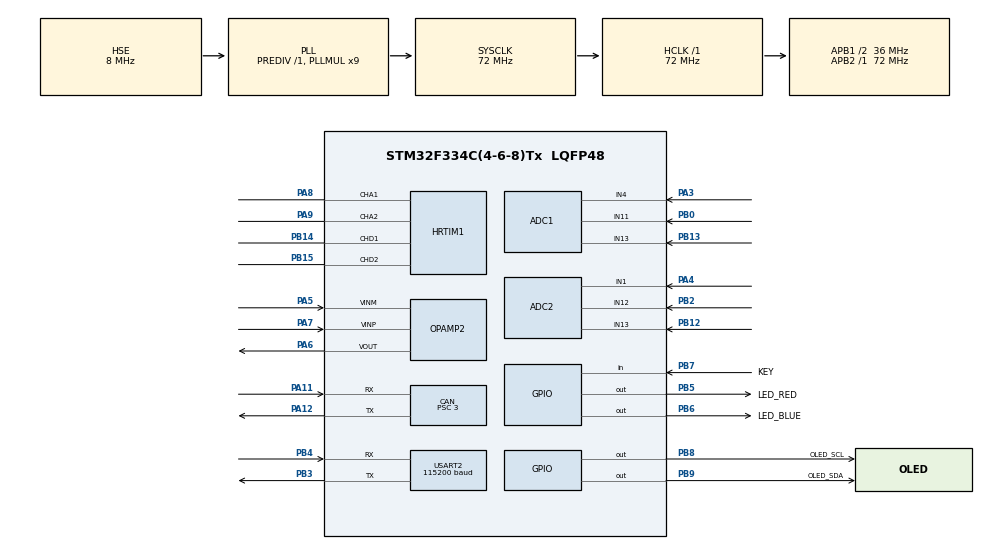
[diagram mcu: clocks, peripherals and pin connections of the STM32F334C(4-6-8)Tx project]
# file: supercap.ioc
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ADC1.Channel-0\#ChannelRegularConversion=ADC_CHANNEL_4
ADC1.Channel-1\#ChannelRegularConversion=ADC_CHANNEL_11
ADC1.Channel-2\#ChannelRegularConversion=ADC_CHANNEL_13
ADC1.ClockPrescaler=ADC_CLOCK_SYNC_PCLK_DIV1
ADC1.ContinuousConvMode=ENABLE
ADC1.DMAContinuousRequests=ENABLE
ADC1.EnableInjectedConversion=DISABLE
ADC1.ExternalTrigConv=ADC_SOFTWARE_START
ADC1.NbrOfConversion=3
ADC1.NbrOfConversionFlag=1
ADC1.Offset-0\#ChannelRegularConversion=0
ADC1.Offset-1\#ChannelRegularConversion=0
ADC1.Offset-2\#ChannelRegularConversion=0
ADC1.OffsetNumber-0\#ChannelRegularConversion=ADC_OFFSET_NONE
ADC1.OffsetNumber-1\#ChannelRegularConversion=ADC_OFFSET_NONE
ADC1.OffsetNumber-2\#ChannelRegularConversion=ADC_OFFSET_NONE
ADC1.Overrun=ADC_OVR_DATA_PRESERVED
ADC1.Rank-0\#ChannelRegularConversion=1
ADC1.Rank-1\#ChannelRegularConversion=2
ADC1.Rank-2\#ChannelRegularConversion=3
ADC1.SamplingTime-0\#ChannelRegularConversion=ADC_SAMPLETIME_601CYCLES_5
ADC1.SamplingTime-1\#ChannelRegularConversion=ADC_SAMPLETIME_601CYCLES_5
ADC1.SamplingTime-2\#ChannelRegularConversion=ADC_SAMPLETIME_601CYCLES_5
ADC1.SubFamily=STM32F334x8
ADC1.master=1
ADC2.Channel-0\#ChannelRegularConversion=ADC_CHANNEL_13
ADC2.Channel-1\#ChannelRegularConversion=ADC_CHANNEL_12
ADC2.Channel-2\#ChannelRegularConversion=ADC_CHANNEL_1
ADC2.ClockPrescaler=ADC_CLOCK_SYNC_PCLK_DIV1
ADC2.ContinuousConvMode=ENABLE
ADC2.DMAContinuousRequests=ENABLE
ADC2.EnableInjectedConversion=DISABLE
ADC2.NbrOfConversion=3
ADC2.NbrOfConversionFlag=1
ADC2.Offset-0\#ChannelRegularConversion=0
ADC2.Offset-1\#ChannelRegularConversion=0
ADC2.Offset-2\#ChannelRegularConversion=0
ADC2.OffsetNumber-0\#ChannelRegularConversion=ADC_OFFSET_NONE
ADC2.OffsetNumber-1\#ChannelRegularConversion=ADC_OFFSET_NONE
ADC2.OffsetNumber-2\#ChannelRegularConversion=ADC_OFFSET_NONE
ADC2.Overrun=ADC_OVR_DATA_PRESERVED
ADC2.Rank-0\#ChannelRegularConversion=1
ADC2.Rank-1\#ChannelRegularConversion=2
ADC2.Rank-2\#ChannelRegularConversion=3
ADC2.SamplingTime-0\#ChannelRegularConversion=ADC_SAMPLETIME_601CYCLES_5
ADC2.SamplingTime-1\#ChannelRegularConversion=ADC_SAMPLETIME_601CYCLES_5
ADC2.SamplingTime-2\#ChannelRegularConversion=ADC_SAMPLETIME_601CYCLES_5
ADC2.SamplingTimeOPAMP-1\#ChannelRegularConversion=ADC_SAMPLETIME_61CYCLES_5
ADC2.SamplingTimeOPAMP-2\#ChannelRegularConversion=ADC_SAMPLETIME_61CYCLES_5
ADC2.SubFamily=STM32F334x8
CAN.ABOM=DISABLE
CAN.BS1=CAN_BS1_7TQ
CAN.BS2=CAN_BS2_4TQ
CAN.CalculateBaudRate=1000000
CAN.CalculateTimeBit=999.99
CAN.CalculateTimeQuantum=83.33333333333334
CAN.NART=DISABLE
CAN.Prescaler=3
CAN.TXFP=ENABLE
Dma.ADC1.0.Direction=DMA_PERIPH_TO_MEMORY
Dma.ADC1.0.Instance=DMA1_Channel1
Dma.ADC1.0.MemDataAlignment=DMA_MDATAALIGN_HALFWORD
Dma.ADC1.0.MemInc=DMA_MINC_ENABLE
Dma.ADC1.0.Mode=DMA_CIRCULAR
Dma.ADC1.0.PeriphDataAlignment=DMA_PDATAALIGN_HALFWORD
Dma.ADC1.0.PeriphInc=DMA_PINC_DISABLE
Dma.ADC1.0.Priority=DMA_PRIORITY_HIGH
Dma.ADC2.1.Direction=DMA_PERIPH_TO_MEMORY
Dma.ADC2.1.Instance=DMA1_Channel2
Dma.ADC2.1.MemDataAlignment=DMA_MDATAALIGN_HALFWORD
Dma.ADC2.1.MemInc=DMA_MINC_ENABLE
Dma.ADC2.1.Mode=DMA_CIRCULAR
Dma.ADC2.1.PeriphDataAlignment=DMA_PDATAALIGN_HALFWORD
Dma.ADC2.1.PeriphInc=DMA_PINC_DISABLE
Dma.ADC2.1.Priority=DMA_PRIORITY_HIGH
Dma.Request0=ADC1
Dma.Request1=ADC2
FREERTOS.Tasks01=defaultTask,24,256,StartDefaultTask,Default,NULL,Dynamic,NULL,NULL;OLED,8,512,StartOLED,As weak,NULL,Dynamic,NULL,NULL;cap_loop,32,512,Startcap_loop,As weak,NULL,Dynamic,NULL,NULL
FREERTOS.configTOTAL_HEAP_SIZE=6000
HRTIM1.CompareUnit1-Output_TA1TA2=HRTIM_COMPAREUNIT_1
HRTIM1.CompareUnit1-Output_TD1TD2=HRTIM_COMPAREUNIT_1
HRTIM1.CompareUnit2-Output_TA1TA2=HRTIM_COMPAREUNIT_2
HRTIM1.CompareUnit2-Output_TD1TD2=HRTIM_COMPAREUNIT_2
HRTIM1.DeadTimeInsertion-Output_TA1TA2=HRTIM_TIMDEADTIMEINSERTION_ENABLED
HRTIM1.DeadTimeInsertion-Output_TD1TD2=HRTIM_TIMDEADTIMEINSERTION_ENABLED
HRTIM1.FallingValue-Output_TA1TA2=300
HRTIM1.FallingValue-Output_TD1TD2=350
HRTIM1.NumberInterruptRequests_Master-MasterTimer=0
HRTIM1.NumberResetSource1-Output_TA1TA2=1
HRTIM1.NumberResetSource1-Output_TD1TD2=1
HRTIM1.NumberResetTrigger-Output_TA1TA2=1
HRTIM1.NumberResetTrigger-Output_TD1TD2=1
HRTIM1.NumberSetSource1-Output_TA1TA2=1
HRTIM1.NumberSetSource1-Output_TD1TD2=1
HRTIM1.Periode_MASTER=46080
HRTIM1.Periode_TA=46080
HRTIM1.Periode_TD=46080
HRTIM1.PreloadEnable-MasterTimer=HRTIM_PRELOAD_ENABLED
HRTIM1.PreloadEnable-Output_TA1TA2=HRTIM_PRELOAD_ENABLED
HRTIM1.PreloadEnable-Output_TD1TD2=HRTIM_PRELOAD_ENABLED
HRTIM1.PrescalerDead-Output_TD1TD2=HRTIM_TIMDEADTIME_PRESCALERRATIO_MUL4
HRTIM1.RepetitionUpdate-MasterTimer=HRTIM_UPDATEONREPETITION_ENABLED
HRTIM1.RepetitionUpdate-Output_TA1TA2=HRTIM_UPDATEONREPETITION_ENABLED
HRTIM1.RepetitionUpdate-Output_TD1TD2=HRTIM_UPDATEONREPETITION_ENABLED
HRTIM1.ResetOutput1_Source1-Output_TA1TA2=HRTIM_OUTPUTRESET_TIMCMP2
HRTIM1.ResetOutput1_Source1-Output_TD1TD2=HRTIM_OUTPUTRESET_TIMCMP2
HRTIM1.ResetTrigger1-Output_TA1TA2=HRTIM_TIMRESETTRIGGER_MASTER_PER
HRTIM1.ResetTrigger1-Output_TD1TD2=HRTIM_TIMRESETTRIGGER_MASTER_PER
HRTIM1.RisingValue-Output_TA1TA2=300
HRTIM1.RisingValue-Output_TD1TD2=350
HRTIM1.SetOutput1_Source1-Output_TA1TA2=HRTIM_OUTPUTSET_TIMCMP1
HRTIM1.SetOutput1_Source1-Output_TD1TD2=HRTIM_OUTPUTSET_TIMCMP1
Mcu.Family=STM32F3
Mcu.Name=STM32F334C(4-6-8)Tx
Mcu.Package=LQFP48
NVIC.CAN_RX0_IRQn=true\:5\:0\:true\:false\:true\:true\:true\:true
NVIC.DMA1_Channel1_IRQn=true\:5\:0\:false\:false\:true\:true\:false\:true
NVIC.DMA1_Channel2_IRQn=true\:5\:0\:false\:false\:true\:true\:false\:true
NVIC.PriorityGroup=NVIC_PRIORITYGROUP_4
NVIC.TIM2_IRQn=true\:5\:0\:true\:false\:true\:true\:true\:true
NVIC.TIM3_IRQn=true\:15\:0\:false\:false\:true\:false\:false\:true
NVIC.TimeBase=TIM3_IRQn
NVIC.TimeBaseIP=TIM3
OPAMP2.SelfCalibration=Disable
PA11.Mode=CAN_Activate
PA11.Signal=CAN_RX
PA12.Mode=CAN_Activate
PA12.Signal=CAN_TX
PA13.Mode=Serial_Wire
PA13.Signal=SYS_JTMS-SWDIO
PA14.Mode=Serial_Wire
PA14.Signal=SYS_JTCK-SWCLK
PA3.Mode=IN4-Single-Ended
PA3.Signal=ADC1_IN4
PA4.Mode=IN1-Single-Ended
PA4.Signal=ADC2_IN1
PA5.Mode=Standalone
PA5.Signal=OPAMP2_VINM
PA6.Mode=Standalone
PA6.Signal=OPAMP2_VOUT
PA7.Mode=Standalone
PA7.Signal=OPAMP2_VINP
PA8.Mode=Output_TA1TA2
PA8.Signal=HRTIM1_CHA1
PA9.Mode=Output_TA1TA2
PA9.Signal=HRTIM1_CHA2
PB0.Mode=IN11-Single-Ended
PB0.Signal=ADC1_IN11
PB12.Mode=IN13-Single-Ended
PB12.Signal=ADC2_IN13
PB13.Mode=IN13-Single-Ended
PB13.Signal=ADC1_IN13
PB14.Mode=Output_TD1TD2
PB14.Signal=HRTIM1_CHD1
PB15.Mode=Output_TD1TD2
PB15.Signal=HRTIM1_CHD2
PB2.Mode=IN12-Single-Ended
PB2.Signal=ADC2_IN12
PB3.Mode=Asynchronous
PB3.Signal=USART2_TX
PB4.Mode=Asynchronous
PB4.Signal=USART2_RX
PB5.GPIO_Label=LED_RED
PB5.Signal=GPIO_Output
PB6.GPIO_Label=LED_BLUE
PB6.Signal=GPIO_Output
PB7.GPIO_Label=KEY
PB7.Signal=GPIO_Input
PB8.GPIO_Label=OLED_SCL
PB8.GPIO_Speed=GPIO_SPEED_FREQ_HIGH
PB8.Signal=GPIO_Output
PB9.GPIO_Label=OLED_SDA
PB9.GPIO_ModeDefaultOutputPP=GPIO_MODE_OUTPUT_OD
PB9.GPIO_PuPd=GPIO_NOPULL
PB9.GPIO_Speed=GPIO_SPEED_FREQ_HIGH
PB9.Signal=GPIO_Output
PF0\ /\ OSC_IN.Mode=HSE-External-Oscillator
PF0\ /\ OSC_IN.Signal=RCC_OSC_IN
PF1\ /\ OSC_OUT.Mode=HSE-External-Oscillator
PF1\ /\ OSC_OUT.Signal=RCC_OSC_OUT
ProjectManager.HeapSize=0x200
ProjectManager.StackSize=0x400
ProjectManager.TargetToolchain=MDK-ARM V5.32
RCC.AHBFreq_Value=72000000
RCC.APB1CLKDivider=RCC_HCLK_DIV2
RCC.APB1Freq_Value=36000000
RCC.APB1TimFreq_Value=72000000
RCC.APB2Freq_Value=72000000
RCC.APB2TimFreq_Value=72000000
RCC.CortexFreq_Value=72000000
RCC.HCLKFreq_Value=72000000
RCC.HRTIMSelection=RCC_HRTIM1CLK_PLLCLK
RCC.HSE_VALUE=8000000
RCC.HSI_VALUE=8000000
RCC.LSE_VALUE=32768
RCC.PLLMUL=RCC_PLL_MUL9
RCC.PLLSourceVirtual=RCC_PLLSOURCE_HSE
RCC.SYSCLKFreq_VALUE=72000000
RCC.SYSCLKSourceVirtual=RCC_SYSCLKSOURCE_PLLCLK
TIM2.AutoReloadPreload=TIM_AUTORELOAD_PRELOAD_ENABLE
TIM2.Period=99
TIM2.Prescaler=71
USART2.BaudRate=115200
USART2.VirtualMode-Asynchronous=VM_ASYNC
VP_FREERTOS_VS_CMSIS_V2.Mode=CMSIS_V2
VP_HRTIM1_VS_hrtimMasterTimerNoOutput.Mode=MasterTimer
VP_SYS_VS_tim3.Mode=TIM3
VP_TIM2_VS_ClockSourceINT.Mode=Internal
board=custom

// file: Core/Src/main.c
/* USER CODE BEGIN Header */
/**
  ******************************************************************************
  * @file           : main.c
  * @brief          : Main program body
  ******************************************************************************
  * @attention
  *
  * <h2><center>&copy; Copyright (c) 2021 STMicroelectronics.
  * All rights reserved.</center></h2>
  *
  * This software component is licensed by ST under BSD 3-Clause license,
  * the "License"; You may not use this file except in compliance with the
  * License. You may obtain a copy of the License at:
  *                        opensource.org/licenses/BSD-3-Clause
  *
  ******************************************************************************
  */
/* USER CODE END Header */
#include "main.h"
#include "cmsis_os.h"
#include "adc.h"
#include "can.h"
#include "dma.h"
#include "hrtim.h"
#include "hrtim.h"
#include "opamp.h"
#include "tim.h"
#include "usart.h"
#include "gpio.h"

/* USER CODE BEGIN Includes */
#include "cap.h"
/* USER CODE END Includes */

void SystemClock_Config(void);
void MX_FREERTOS_Init(void);

int main(void)
{

  /* MCU Configuration--------------------------------------------------------*/

  /* Reset of all peripherals, Initializes the Flash interface and the Systick. */
  HAL_Init();

  /* Configure the system clock */
  SystemClock_Config();

  /* Initialize all configured peripherals */
  MX_GPIO_Init();
  MX_CAN_Init();
  MX_DMA_Init();
  MX_ADC1_Init();
  MX_ADC2_Init();
  MX_OPAMP2_Init();
  MX_TIM2_Init();
  MX_HRTIM1_Init();
  MX_USART2_UART_Init();
  /* USER CODE BEGIN 2 */
    system_init();
  /* USER CODE END 2 */

  /* Init scheduler */
  osKernelInitialize();  /* Call init function for freertos objects (in freertos.c) */
  MX_FREERTOS_Init();
  /* Start scheduler */
  osKernelStart();

  /* We should never get here as control is now taken by the scheduler */
  /* Infinite loop */
  while (1)
  {

  }
}

void SystemClock_Config(void)
{
  RCC_OscInitTypeDef RCC_OscInitStruct = {0};
  RCC_ClkInitTypeDef RCC_ClkInitStruct = {0};
  RCC_PeriphCLKInitTypeDef PeriphClkInit = {0};

  /** Initializes the RCC Oscillators according to the specified parameters
  * in the RCC_OscInitTypeDef structure.
  */
  RCC_OscInitStruct.OscillatorType = RCC_OSCILLATORTYPE_HSE;
  RCC_OscInitStruct.HSEState = RCC_HSE_ON;
  RCC_OscInitStruct.HSEPredivValue = RCC_HSE_PREDIV_DIV1;
  RCC_OscInitStruct.HSIState = RCC_HSI_ON;
  RCC_OscInitStruct.PLL.PLLState = RCC_PLL_ON;
  RCC_OscInitStruct.PLL.PLLSource = RCC_PLLSOURCE_HSE;
  RCC_OscInitStruct.PLL.PLLMUL = RCC_PLL_MUL9;
  if (HAL_RCC_OscConfig(&RCC_OscInitStruct) != HAL_OK)
  {
    Error_Handler();
  }
  /** Initializes the CPU, AHB and APB buses clocks
  */
  RCC_ClkInitStruct.ClockType = RCC_CLOCKTYPE_HCLK|RCC_CLOCKTYPE_SYSCLK
                              |RCC_CLOCKTYPE_PCLK1|RCC_CLOCKTYPE_PCLK2;
  RCC_ClkInitStruct.SYSCLKSource = RCC_SYSCLKSOURCE_PLLCLK;
  RCC_ClkInitStruct.AHBCLKDivider = RCC_SYSCLK_DIV1;
  RCC_ClkInitStruct.APB1CLKDivider = RCC_HCLK_DIV2;
  RCC_ClkInitStruct.APB2CLKDivider = RCC_HCLK_DIV1;

  if (HAL_RCC_ClockConfig(&RCC_ClkInitStruct, FLASH_LATENCY_2) != HAL_OK)
  {
    Error_Handler();
  }
  PeriphClkInit.PeriphClockSelection = RCC_PERIPHCLK_HRTIM1;
  PeriphClkInit.Hrtim1ClockSelection = RCC_HRTIM1CLK_PLLCLK;
  if (HAL_RCCEx_PeriphCLKConfig(&PeriphClkInit) != HAL_OK)
  {
    Error_Handler();
  }
}

void HAL_TIM_PeriodElapsedCallback(TIM_HandleTypeDef *htim)
{
  if (htim->Instance == TIM3) {
    HAL_IncTick();
  }
}

void Error_Handler(void)
{
  __disable_irq();
  while (1)
  {
  }
}

/************************ (C) COPYRIGHT STMicroelectronics *****END OF FILE****/

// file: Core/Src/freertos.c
/* USER CODE BEGIN Header */
/**
  ******************************************************************************
  * File Name          : freertos.c
  * Description        : Code for freertos applications
  ******************************************************************************
  * @attention
  *
  * <h2><center>&copy; Copyright (c) 2022 STMicroelectronics.
  * All rights reserved.</center></h2>
  *
  * This software component is licensed by ST under Ultimate Liberty license
  * SLA0044, the "License"; You may not use this file except in compliance with
  * the License. You may obtain a copy of the License at:
  *                             www.st.com/SLA0044
  *
  ******************************************************************************
  */
/* USER CODE END Header */

#include "FreeRTOS.h"
#include "task.h"
#include "main.h"
#include "cmsis_os.h"

/* Definitions for defaultTask */
osThreadId_t defaultTaskHandle;
const osThreadAttr_t defaultTask_attributes = {
  .name = "defaultTask",
  .stack_size = 256 * 4,
  .priority = (osPriority_t) osPriorityNormal,
};
/* Definitions for OLED */
osThreadId_t OLEDHandle;
const osThreadAttr_t OLED_attributes = {
  .name = "OLED",
  .stack_size = 512 * 4,
  .priority = (osPriority_t) osPriorityLow,
};
/* Definitions for cap_loop */
osThreadId_t cap_loopHandle;
const osThreadAttr_t cap_loop_attributes = {
  .name = "cap_loop",
  .stack_size = 512 * 4,
  .priority = (osPriority_t) osPriorityAboveNormal,
};

void StartDefaultTask(void *argument);
void StartOLED(void *argument);
void Startcap_loop(void *argument);

void MX_FREERTOS_Init(void); /* (MISRA C 2004 rule 8.1) */

void MX_FREERTOS_Init(void) {

  /* Create the thread(s) */
  /* creation of defaultTask */
  defaultTaskHandle = osThreadNew(StartDefaultTask, NULL, &defaultTask_attributes);

  /* creation of OLED */
  OLEDHandle = osThreadNew(StartOLED, NULL, &OLED_attributes);

  /* creation of cap_loop */
  cap_loopHandle = osThreadNew(Startcap_loop, NULL, &cap_loop_attributes);

}

void StartDefaultTask(void *argument)
{
  for(;;)
  {
    osDelay(1);
  }
}

__weak void StartOLED(void *argument)
{
  for(;;)
  {
    osDelay(1);
  }
}

__weak void Startcap_loop(void *argument)
{
  for(;;)
  {
    osDelay(1);
  }
}

/************************ (C) COPYRIGHT STMicroelectronics *****END OF FILE****/
